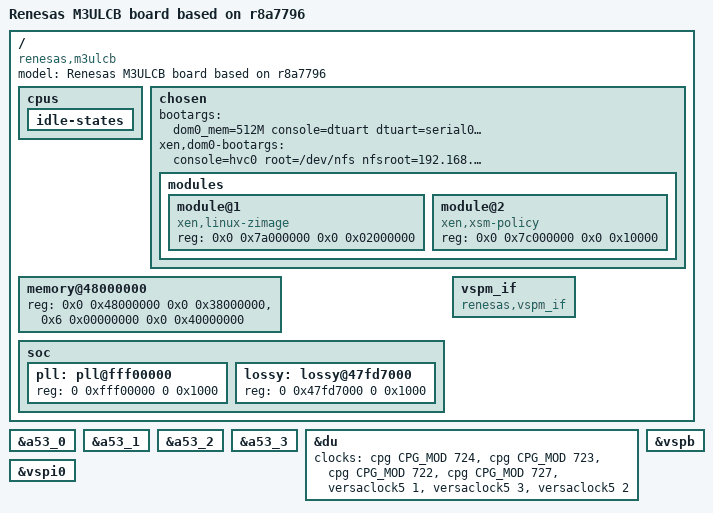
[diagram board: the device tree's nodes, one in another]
/*
 * Device Tree Source for the M3ULCB (R-Car Starter Kit Pro) board
 *
 * Copyright (C) 2016-2017 Renesas Electronics Corp.
 * Copyright (C) 2016 Cogent Embedded, Inc.
 *
 * This file is licensed under the terms of the GNU General Public License
 * version 2.  This program is licensed "as is" without any warranty of any
 * kind, whether express or implied.
 */

/dts-v1/;
#include "r8a7796.dtsi"
#include "ulcb.dtsi"

/ {
	model = "Renesas M3ULCB board based on r8a7796";
	compatible = "renesas,m3ulcb", "renesas,r8a7796";

	cpus {
		idle-states {
			/delete-node/ cpu-sleep-1;
		};
	};

	chosen {
		bootargs = "dom0_mem=512M console=dtuart dtuart=serial0 dom0_max_vcpus=4 bootscrub=0 flask_enforcing=1 loglvl=all";
		xen,dom0-bootargs = "console=hvc0 root=/dev/nfs nfsroot=192.168.1.100:/srv/dom0 ip=192.168.1.10 rw rootwait rootfstype=ext4 ignore_loglevel cma=64M";

		modules {
			#address-cells = <2>;
			#size-cells = <2>;
			module@1 {
				compatible = "xen,linux-zimage", "xen,multiboot-module";
				reg = <0x0 0x7a000000 0x0 0x02000000>;
			};
			module@2 {
				compatible = "xen,xsm-policy", "xen,multiboot-module";
				reg = <0x0 0x7c000000 0x0 0x10000>;
			};
		};
	};

	memory@48000000 {
		device_type = "memory";
		/* first 128MB is reserved for secure area. */
		reg = <0x0 0x48000000 0x0 0x38000000>,
		      <0x6 0x00000000 0x0 0x40000000>;
	};

	soc {
		pll: pll@fff00000 {
			reg = <0 0xfff00000 0 0x1000>;
		};

		lossy: lossy@47fd7000 {
			reg = <0 0x47fd7000 0 0x1000>;
		};

	};

	vspm_if {
		compatible = "renesas,vspm_if";
	};
};

&a53_0 {
	/delete-property/ cpu-idle-states;
};

&a53_1 {
	/delete-property/ cpu-idle-states;
};

&a53_2 {
	/delete-property/ cpu-idle-states;
};

&a53_3 {
	/delete-property/ cpu-idle-states;
};

&du {
	clocks = <&cpg CPG_MOD 724>,
		 <&cpg CPG_MOD 723>,
		 <&cpg CPG_MOD 722>,
		 <&cpg CPG_MOD 727>,
		 <&versaclock5 1>,
		 <&versaclock5 3>,
		 <&versaclock5 2>;
	clock-names = "du.0", "du.1", "du.2", "lvds.0",
		      "dclkin.0", "dclkin.1", "dclkin.2";
};

&vspb {
	status = "okay";
};

&vspi0 {
	status = "okay";
};
